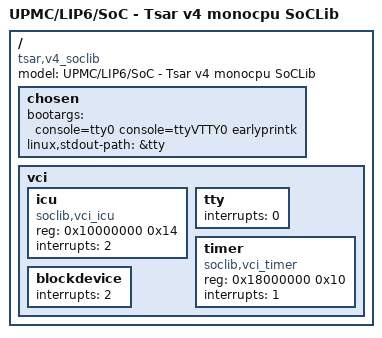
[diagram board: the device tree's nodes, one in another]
/*
 * DTS file for TSAR monocpu on SoCLib
 *
 * Includes the skeleton and specializes it:
 *  - use of vci_icu
 *  - use of vci_timer
 */

/dts-v1/;

/include/ "tsar_soclib_skeleton.dtsi"

/ {
	model = "UPMC/LIP6/SoC - Tsar v4 monocpu SoCLib";
	compatible = "tsar,v4_soclib", "tsar,monocpu_v4_soclib";

	chosen {
		/* the day we have a uart8250 compatible component, we can use
		 * the earlycon param to get earlyprintk */
		/* bootargs = "earlycon=uart8250,mmio,0x00000000"; */

		/* this is for maximum debug */
		/* bootargs = "ignore_loglevel initcall_debug"; */

		/* display console in both framebuffer and tty (the last one
		 * becomes the default one) */
		bootargs = "console=tty0 console=ttyVTTY0 earlyprintk";

		/* default peripheral to use when configuring earlyprintk */
		linux,stdout-path = &tty;
	};

	vci {
		icu: icu {
			/* the vci_icu is a N->1 interrupt controller */
			compatible = "soclib,vci_icu";
			reg = <0x10000000 0x14>;

			/* connected to irq #2 of the cpu */
			interrupts = <2>;

			#interrupt-cells = <1>;
		};

		tty: tty {
			interrupts = <0>;
		};

		timer {
			compatible = "soclib,vci_timer";
			reg = <0x18000000 0x10>;
			interrupts = <1>;
		};

		blockdevice {
			interrupts = <2>;
		};
	};
};
